# PIC32MK0512GPL064 register map
Vendor: Microchip
Registers are 32-bit, read-write, no defined reset value unless marked. A register's access mark holds for its fields unless they carry their own. Addresses are absolute, and some are shared; only a register's first bit layout is shown; [hi:lo] are bit positions; {n}, {i} and the like mark numbered series; 'fields as' and 'values as' point back to an identical list.

## adc_sar_ctrl_upb
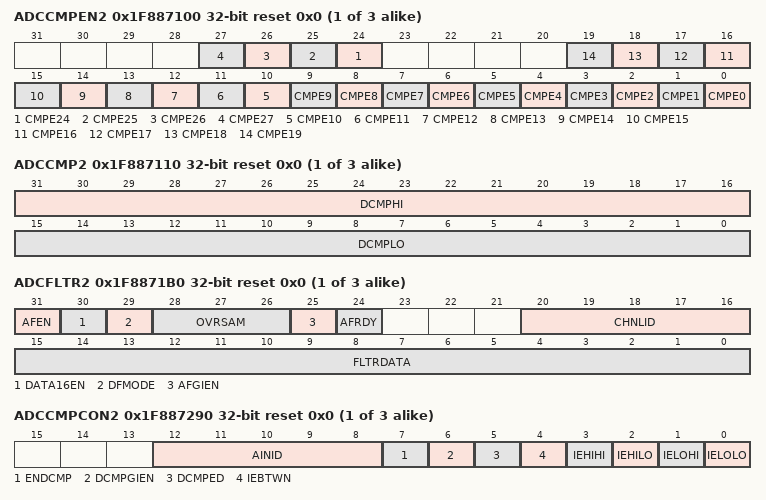
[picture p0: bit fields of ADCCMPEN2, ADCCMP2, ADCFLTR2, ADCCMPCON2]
{0x1F8870C0+0x20*i} ADCCMPEN{i} reset 0x0 (i=2..4)
  [n] CMPE{n} (n=24..27), [n] CMPE{n} (n=0..19)
{0x1F8870D0+0x20*i} ADCCMP{i} reset 0x0 (i=2..4)
  [31:16] DCMPHI, [15:0] DCMPLO
{0x1F887190+0x10*i} ADCFLTR{i} reset 0x0 (i=2..4)
  [31] AFEN, [30] DATA16EN, [29] DFMODE, [28:26] OVRSAM, [25] AFGIEN, [24] AFRDY ro, [20:16] CHNLID, [15:0] FLTRDATA ro
{0x1F887270+0x10*i} ADCCMPCON{i} reset 0x0 (i=2..4)
  [12:8] AINID ro, [7] ENDCMP, [6] DCMPGIEN, [5] DCMPED ro, [4] IEBTWN, [3] IEHIHI, [2] IEHILO, [1] IELOHI, [0] IELOLO
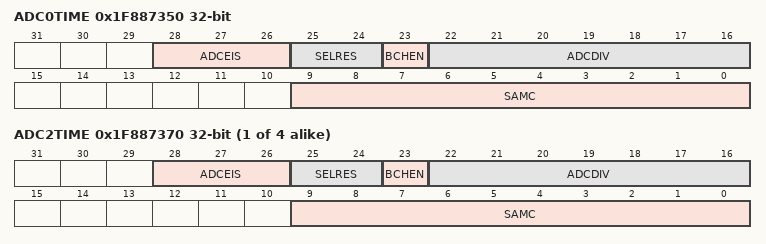
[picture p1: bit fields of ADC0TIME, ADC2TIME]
0x1F887350 ADC0TIME — (power-on value ---00000x0000000------0000000000)
  [28:26] ADCEIS, [25:24] SELRES, [23] BCHEN, [22:16] ADCDIV, [9:0] SAMC
{0x1F887350+0x10*i} ADC{i}TIME (i=2..5) — (power-on value ---00000x0000000------0000000000)
  fields as ADC0TIME

## USB1
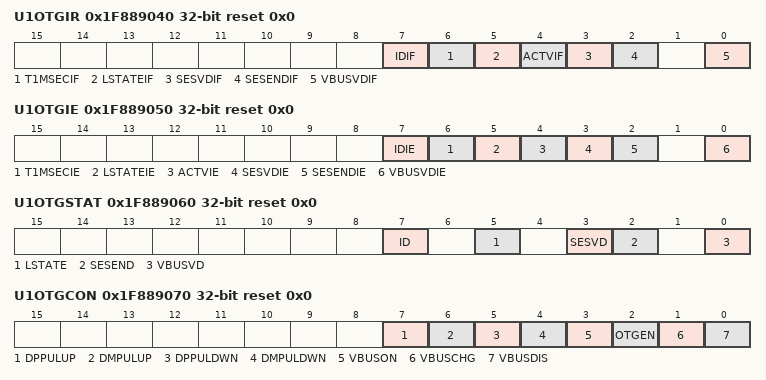
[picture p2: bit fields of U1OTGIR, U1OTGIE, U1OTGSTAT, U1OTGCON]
0x1F889040 U1OTGIR reset 0x0
  [7] IDIF, [6] T1MSECIF, [5] LSTATEIF, [4] ACTVIF, [3] SESVDIF, [2] SESENDIF, [0] VBUSVDIF
0x1F889050 U1OTGIE reset 0x0
  [7] IDIE, [6] T1MSECIE, [5] LSTATEIE, [4] ACTVIE, [3] SESVDIE, [2] SESENDIE, [0] VBUSVDIE
0x1F889060 U1OTGSTAT reset 0x0
  [7] ID, [5] LSTATE, [3] SESVD, [2] SESEND, [0] VBUSVD
0x1F889070 U1OTGCON reset 0x0
  [7] DPPULUP, [6] DMPULUP, [5] DPPULDWN, [4] DMPULDWN, [3] VBUSON, [2] OTGEN, [1] VBUSCHG, [0] VBUSDIS
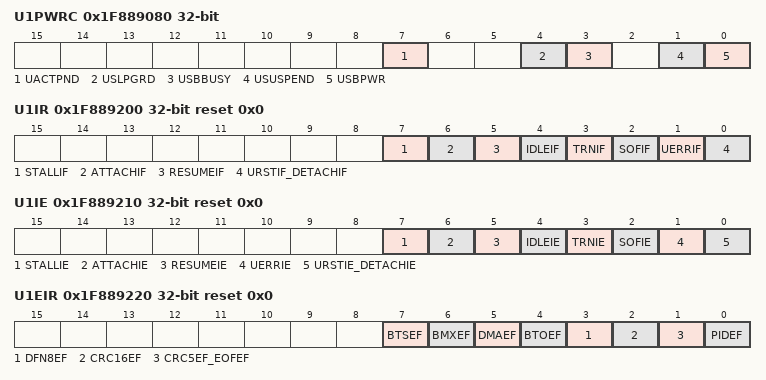
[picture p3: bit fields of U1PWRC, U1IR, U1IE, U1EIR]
0x1F889080 U1PWRC — (power-on value ------------------------0--0x-00)
  [7] UACTPND ro, [4] USLPGRD, [3] USBBUSY, [1] USUSPEND, [0] USBPWR
0x1F889200 U1IR reset 0x0
  [7] STALLIF, [6] ATTACHIF, [5] RESUMEIF, [4] IDLEIF, [3] TRNIF, [2] SOFIF, [1] UERRIF, [0] URSTIF_DETACHIF
0x1F889210 U1IE reset 0x0
  [7] STALLIE, [6] ATTACHIE, [5] RESUMEIE, [4] IDLEIE, [3] TRNIE, [2] SOFIE, [1] UERRIE, [0] URSTIE_DETACHIE
0x1F889220 U1EIR reset 0x0
  [7] BTSEF, [6] BMXEF, [5] DMAEF, [4] BTOEF, [3] DFN8EF, [2] CRC16EF, [1] CRC5EF_EOFEF, [0] PIDEF
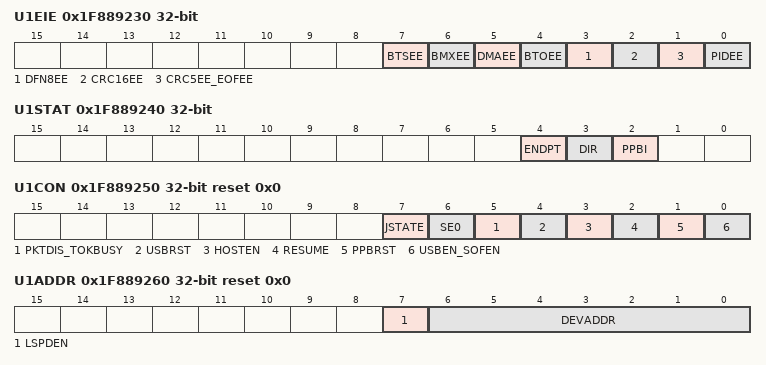
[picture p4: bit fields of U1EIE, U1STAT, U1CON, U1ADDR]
0x1F889230 U1EIE — (power-on value ------------------------0000000x)
  [7] BTSEE, [6] BMXEE, [5] DMAEE, [4] BTOEE, [3] DFN8EE, [2] CRC16EE, [1] CRC5EE_EOFEE, [0] PIDEE
0x1F889240 U1STAT ro
  [4] ENDPT, [3] DIR, [2] PPBI
0x1F889250 U1CON reset 0x0
  [7] JSTATE, [6] SE0, [5] PKTDIS_TOKBUSY, [4] USBRST, [3] HOSTEN, [2] RESUME, [1] PPBRST, [0] USBEN_SOFEN
0x1F889260 U1ADDR reset 0x0
  [7] LSPDEN, [6:0] DEVADDR
0x1F889270 U1BDTP1 reset 0x0
  [7:1] BDTPTRL
0x1F889280 U1FRML ro
  [7:0] FRML
0x1F889290 U1FRMH ro
  [2:0] FRMH
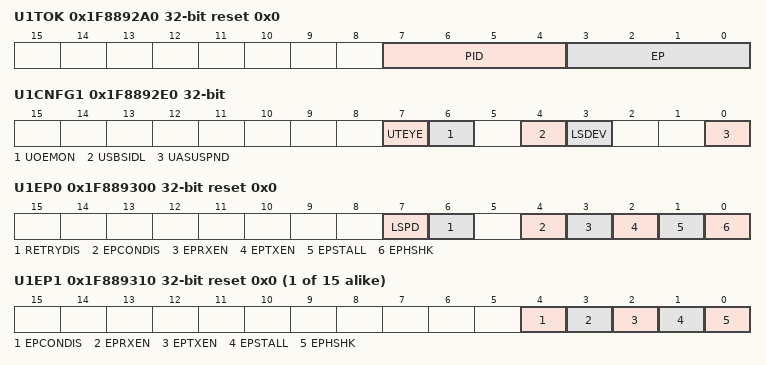
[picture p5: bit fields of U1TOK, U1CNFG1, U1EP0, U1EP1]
0x1F8892A0 U1TOK reset 0x0
  [7:4] PID, [3:0] EP
0x1F8892B0 U1SOF reset 0x0
  [7:0] CNT
0x1F8892C0 U1BDTP2 reset 0x0
  [7:0] BDTPTRH
0x1F8892D0 U1BDTP3 reset 0x0
  [7:0] BDTPTRU
0x1F8892E0 U1CNFG1 — (power-on value ------------------------xxxxx00x)
  [7] UTEYE, [6] UOEMON, [4] USBSIDL, [3] LSDEV, [0] UASUSPND
0x1F889300 U1EP0 reset 0x0
  [7] LSPD, [6] RETRYDIS, [4] EPCONDIS, [3] EPRXEN, [2] EPTXEN, [1] EPSTALL, [0] EPHSHK
{0x1F889300+0x10*i} U1EP{i} reset 0x0 (i=1..15)
  [4] EPCONDIS, [3] EPRXEN, [2] EPTXEN, [1] EPSTALL, [0] EPHSHK

## RTCC
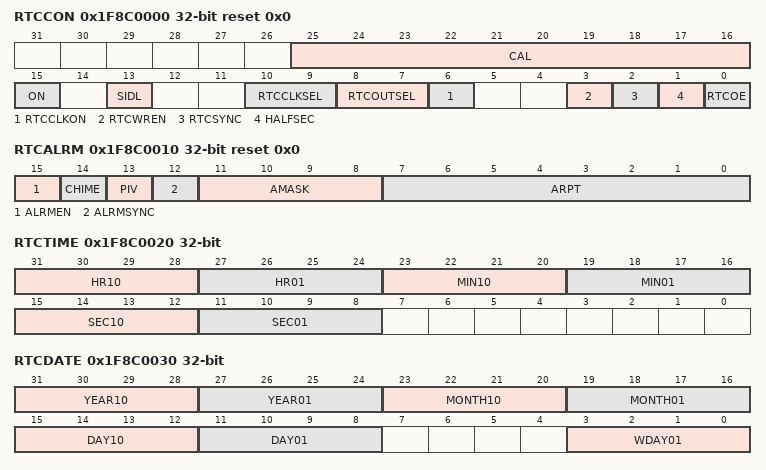
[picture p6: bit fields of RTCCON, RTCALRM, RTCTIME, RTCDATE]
0x1F8C0000 RTCCON reset 0x0
  [25:16] CAL, [15] ON, [13] SIDL, [10:9] RTCCLKSEL, [8:7] RTCOUTSEL, [6] RTCCLKON, [3] RTCWREN, [2] RTCSYNC ro, [1] HALFSEC ro, [0] RTCOE
0x1F8C0010 RTCALRM reset 0x0
  [15] ALRMEN, [14] CHIME, [13] PIV, [12] ALRMSYNC, [11:8] AMASK, [7:0] ARPT
0x1F8C0020 RTCTIME — (power-on value 000xxxxxxxxxxxxx0xxxxxxx--------)
  [31:28] HR10, [27:24] HR01, [23:20] MIN10, [19:16] MIN01, [15:12] SEC10, [11:8] SEC01
0x1F8C0030 RTCDATE — (power-on value xxxxxxxx000xxxxx00xxxxxx----0xxx)
  [31:28] YEAR10, [27:24] YEAR01, [23:20] MONTH10, [19:16] MONTH01, [15:12] DAY10, [11:8] DAY01, [3:0] WDAY01
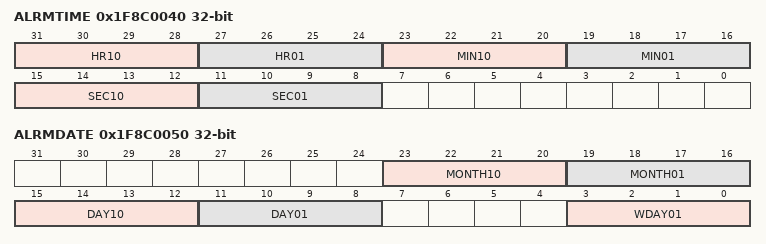
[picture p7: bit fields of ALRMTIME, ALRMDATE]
0x1F8C0040 ALRMTIME — (power-on value 000xxxxx0xxxxxxx0xxxxxxx--------)
  fields as RTCTIME
0x1F8C0050 ALRMDATE — (power-on value --------000xxxxx00xxxxxx----0xxx)
  [23:20] MONTH10, [19:16] MONTH01, [15:12] DAY10, [11:8] DAY01, [3:0] WDAY01

## lpwr_deep_sleep_ctrl
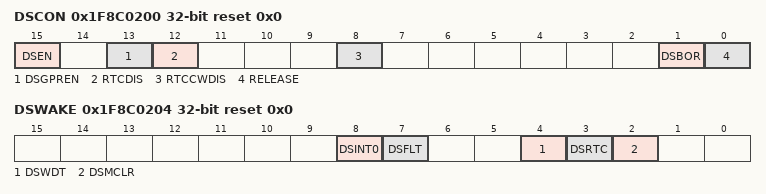
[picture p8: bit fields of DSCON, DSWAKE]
0x1F8C0200 DSCON reset 0x0
  [15] DSEN, [13] DSGPREN, [12] RTCDIS, [8] RTCCWDIS, [1] DSBOR, [0] RELEASE
0x1F8C0204 DSWAKE reset 0x0
  [8] DSINT0, [7] DSFLT, [4] DSWDT, [3] DSRTC, [2] DSMCLR
0x1F8C0208 DSGPR0 reset 0x0
  [31:0] DSGPR
{0x1F8C020C+4i} DSGPR{i} reset 0x0 (i=1..32)
  [31:0] DSGPR

## SB
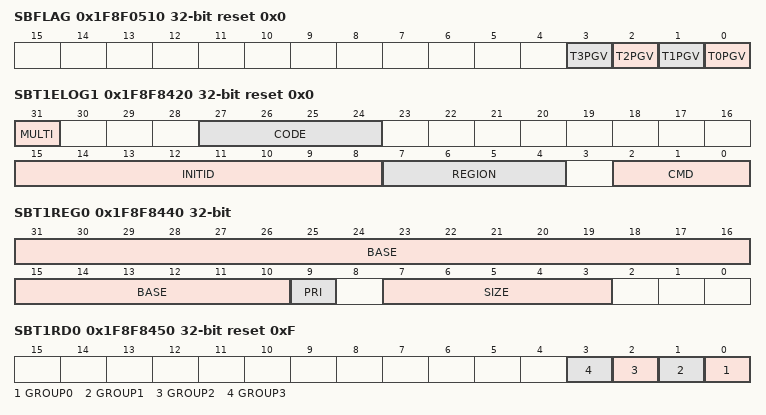
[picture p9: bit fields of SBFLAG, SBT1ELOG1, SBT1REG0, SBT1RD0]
0x1F8F0510 SBFLAG ro reset 0x0
  [n] T{n}PGV (n=0..3)
0x1F8F8420 SBT1ELOG1 reset 0x0
  [31] MULTI, [27:24] CODE, [15:8] INITID ro, [7:4] REGION ro, [2:0] CMD ro
0x1F8F8424 SBT1ELOG2 ro reset 0x0
  [1:0] GROUP
0x1F8F8428 SBT1ECON reset 0x0
  [24] ERRP
0x1F8F8430 SBT1ECLRS ro reset 0x0
  [0] CLEAR
0x1F8F8438 SBT1ECLRM ro reset 0x0
  [0] CLEAR
0x1F8F8440 SBT1REG0 — (power-on value 0000000000000000000000x-00000---)
  [31:10] BASE, [9] PRI ro, [7:3] SIZE
0x1F8F8450 SBT1RD0 reset 0xF
  [n] GROUP{n} (n=0..3)
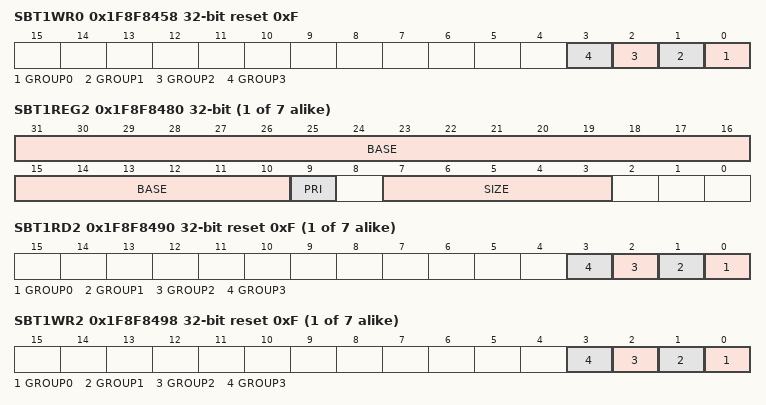
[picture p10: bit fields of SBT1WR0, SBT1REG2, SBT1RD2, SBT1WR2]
0x1F8F8458 SBT1WR0 reset 0xF
  [n] GROUP{n} (n=0..3)
{0x1F8F8440+0x20*i} SBT1REG{i} (i=2..8) — (power-on value 0000000000000000000000x-00000---)
  [31:10] BASE, [9] PRI ro, [7:3] SIZE
{0x1F8F8450+0x20*i} SBT1RD{i} reset 0xF (i=2..8)
  [n] GROUP{n} (n=0..3)
{0x1F8F8458+0x20*i} SBT1WR{i} reset 0xF (i=2..8)
  [n] GROUP{n} (n=0..3)

## DOS_EIP_00136_ssx
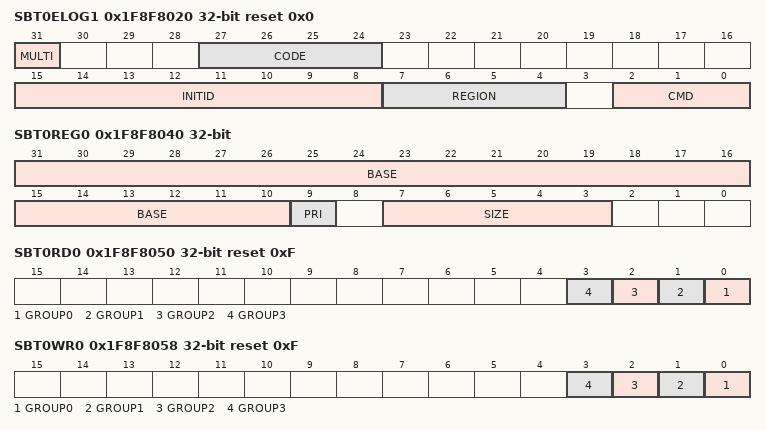
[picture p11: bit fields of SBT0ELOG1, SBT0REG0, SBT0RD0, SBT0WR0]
0x1F8F8020 SBT0ELOG1 reset 0x0
  [31] MULTI, [27:24] CODE, [15:8] INITID ro, [7:4] REGION ro, [2:0] CMD ro
0x1F8F8024 SBT0ELOG2 ro reset 0x0
  [1:0] GROUP
0x1F8F8028 SBT0ECON reset 0x0
  [24] ERRP
0x1F8F8030 SBT0ECLRS ro reset 0x0
  [0] CLEAR
0x1F8F8038 SBT0ECLRM ro reset 0x0
  [0] CLEAR
0x1F8F8040 SBT0REG0 — (power-on value 0000000000000000000000x-00000---)
  [31:10] BASE, [9] PRI ro, [7:3] SIZE
0x1F8F8050 SBT0RD0 reset 0xF
  [n] GROUP{n} (n=0..3)
0x1F8F8058 SBT0WR0 reset 0xF
  [n] GROUP{n} (n=0..3)
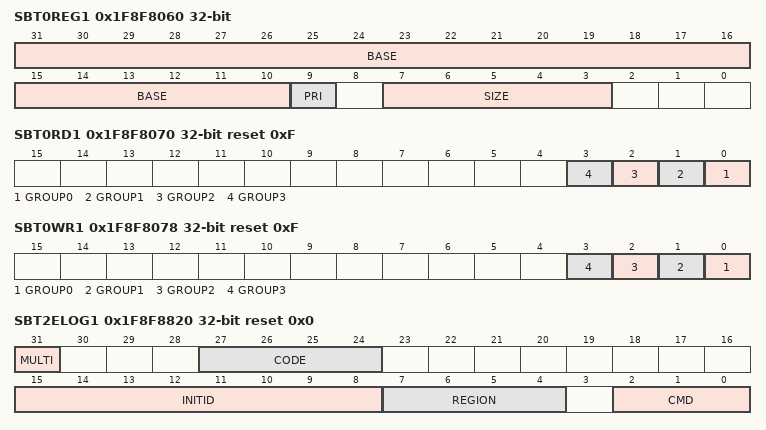
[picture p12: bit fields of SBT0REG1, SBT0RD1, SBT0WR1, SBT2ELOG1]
0x1F8F8060 SBT0REG1 — (power-on value 0000000000000000000000x-00000---)
  [31:10] BASE, [9] PRI ro, [7:3] SIZE
0x1F8F8070 SBT0RD1 reset 0xF
  [n] GROUP{n} (n=0..3)
0x1F8F8078 SBT0WR1 reset 0xF
  [n] GROUP{n} (n=0..3)
0x1F8F8820 SBT2ELOG1 reset 0x0
  fields as SBT0ELOG1
0x1F8F8824 SBT2ELOG2 ro reset 0x0
  [1:0] GROUP
0x1F8F8828 SBT2ECON reset 0x0
  [24] ERRP
0x1F8F8830 SBT2ECLRS ro reset 0x0
  [0] CLEAR
0x1F8F8838 SBT2ECLRM ro reset 0x0
  [0] CLEAR
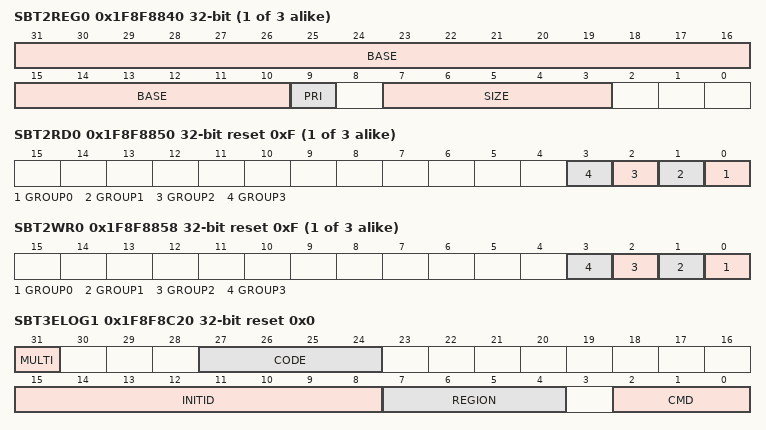
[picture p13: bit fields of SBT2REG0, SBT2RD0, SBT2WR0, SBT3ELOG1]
{0x1F8F8840+0x20*i} SBT2REG{i} (i=0..2) — (power-on value 0000000000000000000000x-00000---)
  [31:10] BASE, [9] PRI ro, [7:3] SIZE
{0x1F8F8850+0x20*i} SBT2RD{i} reset 0xF (i=0..2)
  [n] GROUP{n} (n=0..3)
{0x1F8F8858+0x20*i} SBT2WR{i} reset 0xF (i=0..2)
  [n] GROUP{n} (n=0..3)
0x1F8F8C20 SBT3ELOG1 reset 0x0
  fields as SBT0ELOG1
0x1F8F8C24 SBT3ELOG2 ro reset 0x0
  [1:0] GROUP
0x1F8F8C28 SBT3ECON reset 0x0
  [24] ERRP
0x1F8F8C30 SBT3ECLRS ro reset 0x0
  [0] CLEAR
0x1F8F8C38 SBT3ECLRM ro reset 0x0
  [0] CLEAR
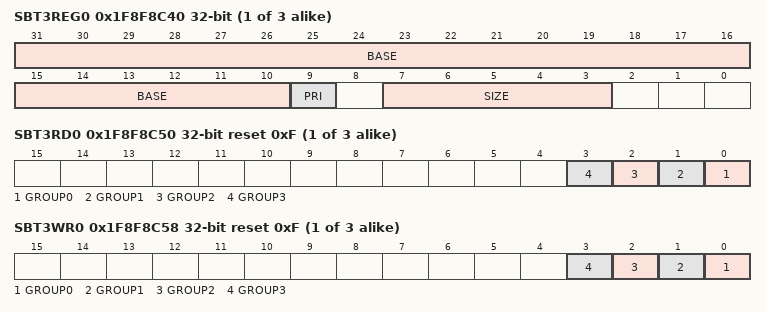
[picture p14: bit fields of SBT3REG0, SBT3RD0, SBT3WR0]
{0x1F8F8C40+0x20*i} SBT3REG{i} (i=0..2) — (power-on value 0000000000000000000000x-00000---)
  [31:10] BASE, [9] PRI ro, [7:3] SIZE
{0x1F8F8C50+0x20*i} SBT3RD{i} reset 0xF (i=0..2)
  [n] GROUP{n} (n=0..3)
{0x1F8F8C58+0x20*i} SBT3WR{i} reset 0xF (i=0..2)
  [n] GROUP{n} (n=0..3)
